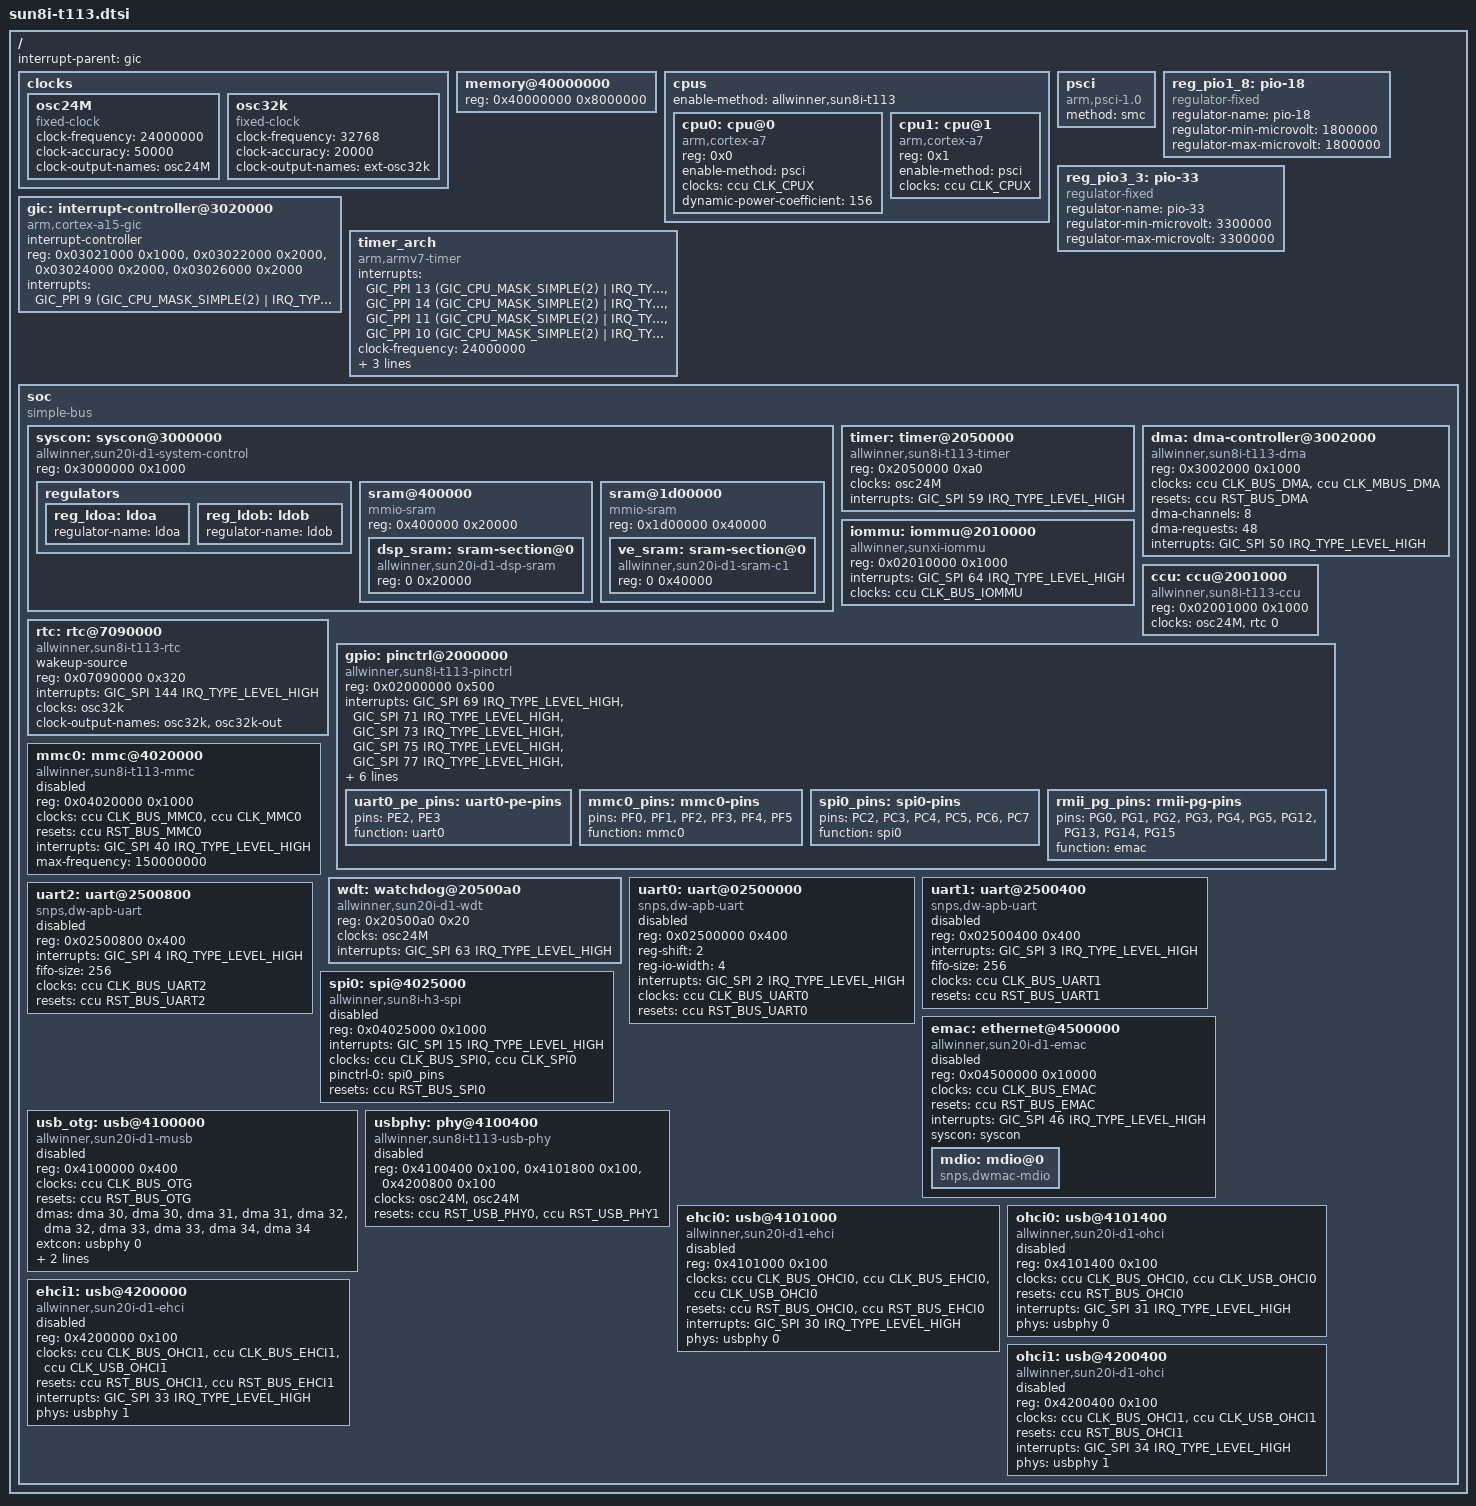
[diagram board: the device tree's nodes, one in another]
/*
* t133 cpu
*/
#include <dt-bindings/clock/sun8i-t113-ccu.h>
#include <dt-bindings/reset/sun8i-t113-ccu.h>
#include <dt-bindings/interrupt-controller/arm-gic.h>

/ {
	#address-cells = <1>;
	#size-cells = <1>;
	interrupt-parent = <&gic>;

	clocks {
		#address-cells = <1>;
		#size-cells = <1>;
		ranges;

		osc24M: osc24M {
			#clock-cells = <0>;
			compatible = "fixed-clock";
			clock-frequency = <24000000>;
			clock-accuracy = <50000>;
			clock-output-names = "osc24M";
		};

		osc32k: osc32k {
			#clock-cells = <0>;
			compatible = "fixed-clock";
			clock-frequency = <32768>;
			clock-accuracy = <20000>;
			clock-output-names = "ext-osc32k";
		};
	};

	 memory@40000000 {
		device_type = "memory";
		reg = <0x40000000 0x8000000>;
    };

    cpus {
		#address-cells = <1>;
		#size-cells = <0>;
		enable-method = "allwinner,sun8i-t113";
		cpu0: cpu@0 {
			device_type = "cpu";
			compatible = "arm,cortex-a7","arm,armv7";
			reg = <0x0>;
			enable-method = "psci";
			clocks = <&ccu CLK_CPUX>;
			dynamic-power-coefficient = <156>;
			// cpu-idle-states = <&CPU_SLEEP &CLUSTER_SLEEP>;
			// operating-points-v2 = <&cpu_opp_table>;
			// #cooling-cells = <2>;
		};

	cpu1: cpu@1 {
			device_type = "cpu";
			compatible = "arm,cortex-a7","arm,armv7";
			reg = <0x1>;
			enable-method = "psci";
			clocks = <&ccu CLK_CPUX>;
			// cpu-idle-states = <&CPU_SLEEP &CLUSTER_SLEEP>;
			// operating-points-v2 = <&cpu_opp_table>;
			// #cooling-cells = <2>;
		};

    };

	psci {
                compatible = "arm,psci-1.0";
                method = "smc";
        };

	reg_pio1_8: pio-18 {
		compatible = "regulator-fixed";
		regulator-name = "pio-18";
		regulator-min-microvolt = <1800000>;
		regulator-max-microvolt = <1800000>;
	};

	reg_pio3_3: pio-33 {
			compatible = "regulator-fixed";
			regulator-name = "pio-33";
			regulator-min-microvolt = <3300000>;
			regulator-max-microvolt = <3300000>;
	};
	gic: interrupt-controller@3020000 {
                compatible = "arm,cortex-a15-gic", "arm,cortex-a9-gic","arm,gic-400";
                #interrupt-cells = <3>;
                #address-cells = <0>;
                interrupt-controller;
                reg = <0x03021000 0x1000>, /* GIC Dist */
                      <0x03022000 0x2000>, /* GIC CPU */
                      <0x03024000 0x2000>, /* GIC VCPU Control */
                      <0x03026000 0x2000>; /* GIC VCPU */
				interrupts = <GIC_PPI 9 (GIC_CPU_MASK_SIMPLE(2) | IRQ_TYPE_LEVEL_LOW)>;
                //interrupts = <GIC_PPI 9 0xf04>; /* GIC Maintenence IRQ */
        };
	timer_arch {
                compatible = "arm,armv7-timer";
                interrupts = <GIC_PPI 13 (GIC_CPU_MASK_SIMPLE(2) | IRQ_TYPE_LEVEL_LOW)>,
                             <GIC_PPI 14 (GIC_CPU_MASK_SIMPLE(2) | IRQ_TYPE_LEVEL_LOW)>,
                             <GIC_PPI 11 (GIC_CPU_MASK_SIMPLE(2) | IRQ_TYPE_LEVEL_LOW)>,
                             <GIC_PPI 10 (GIC_CPU_MASK_SIMPLE(2) | IRQ_TYPE_LEVEL_LOW)>;
                clock-frequency = <24000000>;
                arm,cpu-registers-not-fw-configured;
                interrupt-parent = <&gic>;
                arm,no-tick-in-suspend;
        };

    soc {
		compatible = "simple-bus";
		#address-cells = <1>;
		#size-cells = <1>;
		ranges;

		syscon: syscon@3000000 {
			compatible = "allwinner,sun20i-d1-system-control";
			reg = <0x3000000 0x1000>;
			#address-cells = <1>;
			#size-cells = <1>;
			ranges;

			regulators {
				reg_ldoa: ldoa {
					regulator-name = "ldoa";
				};

				reg_ldob: ldob {
					regulator-name = "ldob";
				};
			};

			sram@400000 {
				compatible = "mmio-sram";
				reg = <0x400000 0x20000>;
				#address-cells = <1>;
				#size-cells = <1>;
				ranges = <0 0x400000 0x20000>;

				/*
				 * This can be further divided into DSP IRAM,
				 * DSP DRAM0, and DSP DRAM1, but the mapping
				 * of all three is controlled by a single bit.
				 */
				dsp_sram: sram-section@0 {
					compatible = "allwinner,sun20i-d1-dsp-sram";
					reg = <0 0x20000>;
				};
			};

			// FIXME: Address is not verified. It is copied from A64/H6.
			sram@1d00000 {
				compatible = "mmio-sram";
				reg = <0x1d00000 0x40000>;
				#address-cells = <1>;
				#size-cells = <1>;
				ranges = <0 0x1d00000 0x40000>;

				ve_sram: sram-section@0 {
					compatible = "allwinner,sun20i-d1-sram-c1",
						     "allwinner,sun4i-a10-sram-c1";
					reg = <0 0x40000>;
				};
			};
		};
		timer: timer@2050000 {
			compatible = "allwinner,sun8i-t113-timer",
				     "allwinner,sun8i-a23-timer";
			reg = <0x2050000 0xa0>;
			clocks = <&osc24M>;
			interrupts = <GIC_SPI 59 IRQ_TYPE_LEVEL_HIGH>;
		};

		dma: dma-controller@3002000 {
			compatible = "allwinner,sun8i-t113-dma";
			reg = <0x3002000 0x1000>;
			clocks = <&ccu CLK_BUS_DMA>, <&ccu CLK_MBUS_DMA>;
			clock-names = "bus", "mbus";
			resets = <&ccu RST_BUS_DMA>;
			#dma-cells = <1>;
			dma-channels = <8>;
			dma-requests = <48>;
			interrupts = <GIC_SPI 50 IRQ_TYPE_LEVEL_HIGH>;
		};

		 iommu: iommu@2010000 {
                compatible = "allwinner,sunxi-iommu";
                reg = <0x02010000 0x1000>;
                interrupts = <GIC_SPI 64 IRQ_TYPE_LEVEL_HIGH>;
                interrupt-names = "iommu-irq";
                clocks = <&ccu CLK_BUS_IOMMU>;
                clock-names = "iommu";
                #iommu-cells = <2>;
                status = "okay";
        };

		ccu: ccu@2001000 {
                        compatible = "allwinner,sun8i-t113-ccu";
                        reg = <0x02001000 0x1000>;
                        clocks = <&osc24M>, <&rtc 0>;
						clock-names = "hosc", "losc";
                        #clock-cells = <1>;
                        #reset-cells = <1>;
                };

		rtc: rtc@7090000 {
                        compatible = "allwinner,sun8i-t113-rtc";
                        #clock-cells = <1>;
                        wakeup-source;
                        reg = <0x07090000 0x320>;
                        interrupts = <GIC_SPI 144 IRQ_TYPE_LEVEL_HIGH>;
						clocks = <&osc32k>;
						clock-output-names = "osc32k", "osc32k-out";
                };

		gpio: pinctrl@2000000 {
			 reg = <0x02000000 0x500>;
			interrupts = <GIC_SPI 69 IRQ_TYPE_LEVEL_HIGH>,  /* AW1859_GIC_Spec: GPIOB: 101-32=69 */
						<GIC_SPI 71 IRQ_TYPE_LEVEL_HIGH>,
						<GIC_SPI 73 IRQ_TYPE_LEVEL_HIGH>,
						<GIC_SPI 75 IRQ_TYPE_LEVEL_HIGH>,
						<GIC_SPI 77 IRQ_TYPE_LEVEL_HIGH>,
						<GIC_SPI 79 IRQ_TYPE_LEVEL_HIGH>;
			compatible = "allwinner,sun8i-t113-pinctrl";
			device_type = "pio";
			clocks = <&ccu CLK_APB0>, <&osc24M>, <&rtc 0>;
                        clock-names = "apb", "hosc", "losc";
			gpio-controller;
			#gpio-cells = <3>;
			interrupt-controller;
			#interrupt-cells = <3>;
			#size-cells = <0>;
			vcc-pf-supply = <&reg_pio1_8>;
			vcc-pfo-supply = <&reg_pio3_3>;

			uart0_pe_pins: uart0-pe-pins {
				pins = "PE2", "PE3";
				function = "uart0";
			};
			mmc0_pins: mmc0-pins {
				pins = "PF0", "PF1", "PF2", "PF3", "PF4", "PF5";
				function = "mmc0";
			};
			spi0_pins: spi0-pins {
				pins = "PC2", "PC3", "PC4", "PC5", "PC6", "PC7";
				function = "spi0";
			};
			rmii_pg_pins: rmii-pg-pins {
				pins = "PG0", "PG1", "PG2", "PG3", "PG4",
				       "PG5", "PG12", "PG13", "PG14", "PG15";
				function = "emac";
			};


		};

		mmc0: mmc@4020000 {
			compatible = "allwinner,sun8i-t113-mmc";
			reg = <0x04020000 0x1000>;
			clocks = <&ccu CLK_BUS_MMC0>, <&ccu CLK_MMC0>;
			clock-names = "ahb", "mmc";
			resets = <&ccu RST_BUS_MMC0>;
			reset-names = "ahb";
			interrupts = <GIC_SPI 40 IRQ_TYPE_LEVEL_HIGH>;
			max-frequency = <150000000>;
			status = "disabled";
			#address-cells = <1>;
			#size-cells = <0>;
		};
		wdt: watchdog@20500a0 {
			compatible = "allwinner,sun20i-d1-wdt";
			reg = <0x20500a0 0x20>;
			clocks = <&osc24M>;
			interrupts = <GIC_SPI 63 IRQ_TYPE_LEVEL_HIGH>;
		};

        uart0: uart@02500000 {
			compatible = "snps,dw-apb-uart";
			reg = <0x02500000 0x400>;
			reg-shift = <2>;
			reg-io-width = <4>;
			interrupts = <GIC_SPI 2 IRQ_TYPE_LEVEL_HIGH>;
			clocks = <&ccu CLK_BUS_UART0>;
			resets = <&ccu RST_BUS_UART0>;
			status = "disabled";
		};

		uart1: uart@2500400 {
			compatible = "snps,dw-apb-uart";
			reg = <0x02500400 0x400>;
			interrupts = <GIC_SPI 3 IRQ_TYPE_LEVEL_HIGH>;
			fifo-size = <256>;
			clocks = <&ccu CLK_BUS_UART1>;
			clock-names = "uart1";
			resets = <&ccu RST_BUS_UART1>;
			status = "disabled";
		};

		uart2: uart@2500800 {
			compatible = "snps,dw-apb-uart";
			reg = <0x02500800 0x400>;
			interrupts = <GIC_SPI 4 IRQ_TYPE_LEVEL_HIGH>;
			fifo-size = <256>;
			clocks = <&ccu CLK_BUS_UART2>;
			clock-names = "uart2";
			resets = <&ccu RST_BUS_UART2>;
			status = "disabled";
		};


		spi0: spi@4025000 {
			compatible = "allwinner,sun8i-h3-spi";
			reg = <0x04025000 0x1000>;
			interrupts = <GIC_SPI 15 IRQ_TYPE_LEVEL_HIGH>;
			clocks = <&ccu CLK_BUS_SPI0>, <&ccu CLK_SPI0>;
			clock-names = "ahb", "mod";
			pinctrl-names = "default";
			pinctrl-0 = <&spi0_pins>;
			resets = <&ccu RST_BUS_SPI0>;
			status = "disabled";
			#address-cells = <1>;
			#size-cells = <0>;
		};
		emac: ethernet@4500000 {
			compatible = "allwinner,sun20i-d1-emac",
				     "allwinner,sun50i-a64-emac";
			reg = <0x04500000 0x10000>;
			clocks = <&ccu CLK_BUS_EMAC>;
			clock-names = "stmmaceth";
			resets = <&ccu RST_BUS_EMAC>;
			reset-names = "stmmaceth";
			interrupts = <GIC_SPI 46 IRQ_TYPE_LEVEL_HIGH>;
			interrupt-names = "macirq";
			syscon = <&syscon>;
			status = "disabled";

			mdio: mdio@0 {
				compatible = "snps,dwmac-mdio";
				#address-cells = <1>;
				#size-cells = <0>;
			};
		};

		usb_otg: usb@4100000 {
			compatible = "allwinner,sun20i-d1-musb",
				     "allwinner,sun8i-a33-musb";
			reg = <0x4100000 0x400>;
			clocks = <&ccu CLK_BUS_OTG>;
			resets = <&ccu RST_BUS_OTG>;
			dmas = <&dma 30>, <&dma 30>,
			       <&dma 31>, <&dma 31>,
			       <&dma 32>, <&dma 32>,
			       <&dma 33>, <&dma 33>,
			       <&dma 34>, <&dma 34>;
			dma-names = "ep1_rx", "ep1_tx",
				    "ep2_rx", "ep2_tx",
				    "ep3_rx", "ep3_tx",
				    "ep4_rx", "ep4_tx",
				    "ep5_rx", "ep5_tx";
			extcon = <&usbphy 0>;
			interrupts = <GIC_SPI 29 IRQ_TYPE_LEVEL_HIGH>;
			interrupt-names = "mc";
			phys = <&usbphy 0>;
			phy-names = "usb";
			status = "disabled";
		};

		usbphy: phy@4100400 {
			compatible = "allwinner,sun8i-t113-usb-phy";
			reg = <0x4100400 0x100>,
			      <0x4101800 0x100>,
			      <0x4200800 0x100>;
			reg-names = "phy_ctrl",
				    "pmu0",
				    "pmu1";
			clocks = <&osc24M>,
				 <&osc24M>;
			clock-names = "usb0_phy",
				      "usb1_phy";
			resets = <&ccu RST_USB_PHY0>,
				 <&ccu RST_USB_PHY1>;
			reset-names = "usb0_reset",
				      "usb1_reset";
			#phy-cells = <1>;
			status = "disabled";
		};

		ehci0: usb@4101000 {
			compatible = "allwinner,sun20i-d1-ehci",
				     "generic-ehci";
			reg = <0x4101000 0x100>;
			clocks = <&ccu CLK_BUS_OHCI0>,
				 <&ccu CLK_BUS_EHCI0>,
				 <&ccu CLK_USB_OHCI0>;
			resets = <&ccu RST_BUS_OHCI0>,
				 <&ccu RST_BUS_EHCI0>;
			interrupts = <GIC_SPI 30 IRQ_TYPE_LEVEL_HIGH>;
			phys = <&usbphy 0>;
			phy-names = "usb";
			status = "disabled";
		};

		ohci0: usb@4101400 {
			compatible = "allwinner,sun20i-d1-ohci",
				     "generic-ohci";
			reg = <0x4101400 0x100>;
			clocks = <&ccu CLK_BUS_OHCI0>,
				 <&ccu CLK_USB_OHCI0>;
			resets = <&ccu RST_BUS_OHCI0>;
			interrupts = <GIC_SPI 31 IRQ_TYPE_LEVEL_HIGH>;
			phys = <&usbphy 0>;
			phy-names = "usb";
			status = "disabled";
		};

		ehci1: usb@4200000 {
			compatible = "allwinner,sun20i-d1-ehci",
				     "generic-ehci";
			reg = <0x4200000 0x100>;
			clocks = <&ccu CLK_BUS_OHCI1>,
				 <&ccu CLK_BUS_EHCI1>,
				 <&ccu CLK_USB_OHCI1>;
			resets = <&ccu RST_BUS_OHCI1>,
				 <&ccu RST_BUS_EHCI1>;
			interrupts = <GIC_SPI 33 IRQ_TYPE_LEVEL_HIGH>;
			phys = <&usbphy 1>;
			phy-names = "usb";
			status = "disabled";
		};

		ohci1: usb@4200400 {
			compatible = "allwinner,sun20i-d1-ohci",
				     "generic-ohci";
			reg = <0x4200400 0x100>;
			clocks = <&ccu CLK_BUS_OHCI1>,
				 <&ccu CLK_USB_OHCI1>;
			resets = <&ccu RST_BUS_OHCI1>;
			interrupts = <GIC_SPI 34 IRQ_TYPE_LEVEL_HIGH>;
			phys = <&usbphy 1>;
			phy-names = "usb";
			status = "disabled";
		};

    };
};
